VERSION "HIPBNYYYYYYYYYYYYYYYYYYYYYYYYYYYYYYYYYYYYY/4/%%%/4/'%**4YYY///"
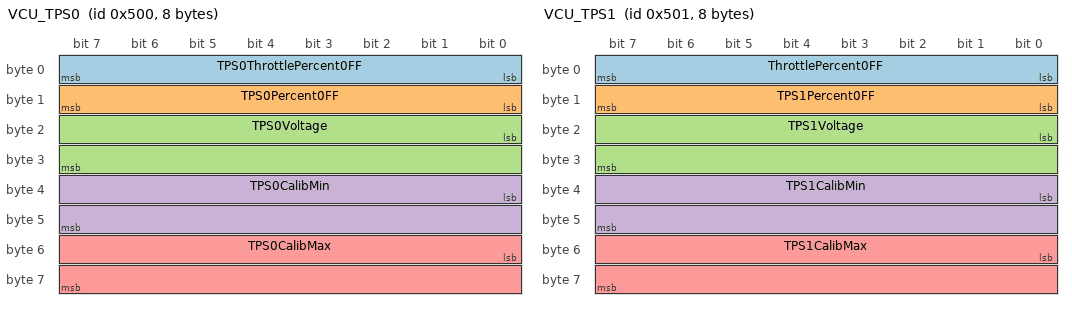
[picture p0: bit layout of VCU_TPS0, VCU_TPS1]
BO_ 1280 VCU_TPS0: 8 VCU
 SG_ TPS0ThrottlePercent0FF : 0|8@1+ (0.392156862746,0) [0|100.00000000023] "%" VCU
 SG_ TPS0Percent0FF : 8|8@1+ (0.392156862746,0) [0|100.00000000023] "%" VCU
 SG_ TPS0Voltage : 16|16@1+ (0.001,0) [0|65.535] "V" VCU
 SG_ TPS0CalibMin : 32|16@1+ (0.001,0) [0|65.535] "V" VCU
 SG_ TPS0CalibMax : 48|16@1+ (0.001,0) [0|65.535] "V" VCU

BO_ 1281 VCU_TPS1: 8 VCU
 SG_ ThrottlePercent0FF : 0|8@1+ (1,0) [0|255] "" VCU
 SG_ TPS1Percent0FF : 8|8@1+ (0.392156862746,0) [0|100.00000000023] "%" VCU
 SG_ TPS1Voltage : 16|16@1+ (0.001,0) [0|65.535] "V" VCU
 SG_ TPS1CalibMin : 32|16@1+ (0.001,0) [0|65.535] "V" VCU
 SG_ TPS1CalibMax : 48|16@1+ (0.001,0) [0|65.535] "V" VCU

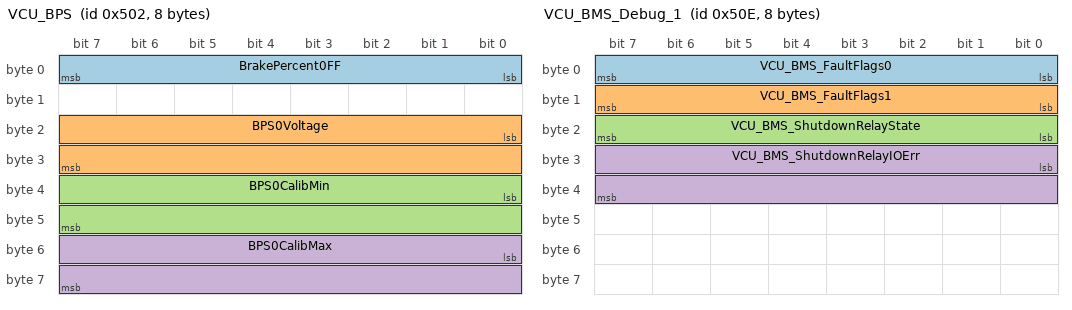
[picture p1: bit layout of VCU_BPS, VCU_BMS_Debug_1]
BO_ 1282 VCU_BPS: 8 VCU
SG_ BrakePercent0FF : 0|8@1+ (0.392156862746,0) [0|100.00000000023] "%" VCU
SG_ BPS0Voltage : 16|16@1+ (0.001,0) [0|65.535] "V" VCU
SG_ BPS0CalibMin : 32|16@1+ (0.001,0) [0|65.535] "V" VCU
SG_ BPS0CalibMax : 48|16@1+ (0.001,0) [0|65.535] "V" VCU

BO_ 1286 VCU_Safety_Checker: 8 VCU
 SG_ VCU_FAULT_TPS_OutOfRange : 0|1@1+ (1,0) [0|1] "" VCU
 SG_ VCU_FAULT_BPS_OutOfRange : 1|1@1+ (1,0) [0|1] "" VCU
 SG_ VCU_FAULT_TPS_PowerFailure : 2|1@1+ (1,0) [0|1] "" VCU
 SG_ VCU_FAULT_BPS_PowerFailure : 3|1@1+ (1,0) [0|1] "" VCU
 SG_ VCU_FAULT_TPS_SignalFailure : 4|1@1+ (1,0) [0|1] "" VCU
 SG_ VCU_FAULT_BPS_SignalFailure : 5|1@1+ (1,0) [0|1] "" VCU
 SG_ VCU_FAULT_TPS_NotCalibrated : 6|1@1+ (1,0) [0|1] "" VCU
 SG_ VCU_FAULT_BPS_NotCalibrated : 7|1@1+ (1,0) [0|1] "" VCU
 SG_ VCU_FAULT_TPS_OutOfSync : 8|1@1+ (1,0) [0|1] "" VCU
 SG_ VCU_FAULT_TPSBPS_Implausible : 10|1@1+ (1,0) [0|1] "" VCU
 SG_ VCU_FAULT_BSPD_SoftFault : 12|1@1+ (1,0) [0|1] "" VCU
 SG_ VCU_FAULT_LVS_BatteryEmpty : 16|1@1+ (1,0) [0|1] "" VCU
 SG_ VCU_WARNING_LVS_BatteryLow : 32|1@1+ (1,0) [0|1] "" VCU
 SG_ VCU_WARNING_HVIL_OverrideEn : 38|1@1+ (1,0) [0|1] "" VCU
 SG_ VCU_WARNING_SAFETY_BypassEn : 39|1@1+ (1,0) [0|1] "" VCU
 SG_ VCU_NOTICE_HVIL_TermSenseLost : 48|1@1+ (1,0) [0|1] "" VCU
 SG_ VCU_NOTICE_BMS_Over75kW : 52|1@1+ (1,0) [0|1] "" VCU
 SG_ VCU_NOTICE_MCM_Over75kW : 53|1@1+ (1,0) [0|1] "" VCU

BO_ 1288 VCU_Regen_Settings: 8 VCU

BO_ 1291 AMK_VCU_Debug: 8 mcm
 SG_ Inverter1_StartUpStage : 0|8@1+ (1,0) [0|10] "" VCU
 SG_ Inverter2_StartUpStage : 8|8@1+ (1,0) [0|10] "" VCU

BO_ 1294 VCU_BMS_Debug_1: 8 VCU
 SG_ VCU_BMS_FaultFlags0 : 0|8@1+ (1,0) [0|255] "" VCU
 SG_ VCU_BMS_FaultFlags1 : 8|8@1+ (1,0) [0|255] "" VCU
 SG_ VCU_BMS_ShutdownRelayState : 16|8@1+ (1,0) [0|255] "" VCU
 SG_ VCU_BMS_ShutdownRelayIOErr : 24|16@1+ (1,0) [0|255] "" VCU

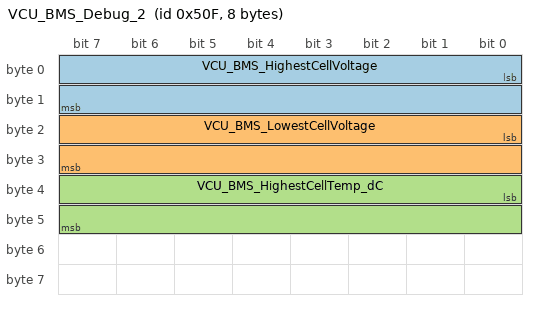
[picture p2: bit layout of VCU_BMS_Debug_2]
BO_ 1295 VCU_BMS_Debug_2: 8 VCU
 SG_ VCU_BMS_HighestCellVoltage : 0|16@1+ (1,0) [0|255] "V" VCU
 SG_ VCU_BMS_LowestCellVoltage : 16|16@1+ (1,0) [0|255] "V" VCU
 SG_ VCU_BMS_HighestCellTemp_dC : 32|16@1- (1,0) [-32768|32767] "C" VCU

BO_ 1296 VCU_80kW_Debug: 8 VCU
 SG_ VCU_MCM_Power : 0|32@1+ (1,0) [0|1000000] "W" VCU
 SG_ VCU_Safety_Checker_Notices : 32|32@1+ (1,0) [0|1000000] "" VCU
